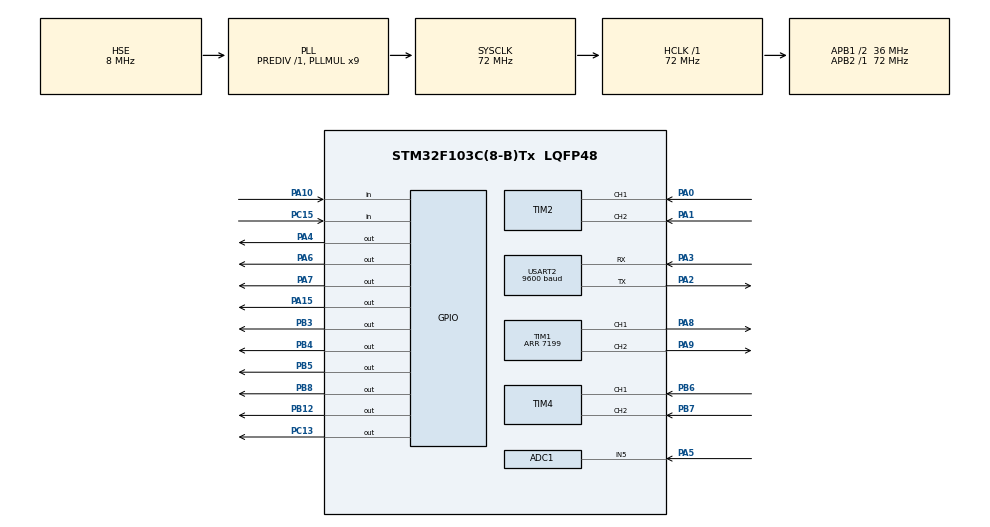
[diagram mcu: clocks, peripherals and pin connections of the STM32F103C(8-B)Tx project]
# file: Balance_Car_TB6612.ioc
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ADC1.Channel-2\#ChannelRegularConversion=ADC_CHANNEL_5
ADC1.NbrOfConversionFlag=1
ADC1.Rank-2\#ChannelRegularConversion=1
ADC1.SamplingTime-2\#ChannelRegularConversion=ADC_SAMPLETIME_1CYCLE_5
ADC1.master=1
Mcu.Family=STM32F1
Mcu.Name=STM32F103C(8-B)Tx
Mcu.Package=LQFP48
NVIC.PriorityGroup=NVIC_PRIORITYGROUP_4
NVIC.TIM3_IRQn=true\:0\:0\:false\:false\:true\:true\:true\:true
NVIC.USART2_IRQn=true\:2\:0\:true\:false\:true\:true\:true\:true
PA0-WKUP.Signal=S_TIM2_CH1_ETR
PA1.Signal=S_TIM2_CH2
PA10.GPIO_PuPd=GPIO_PULLUP
PA10.Signal=GPIO_Input
PA13.Mode=Serial_Wire
PA13.Signal=SYS_JTMS-SWDIO
PA14.Mode=Serial_Wire
PA14.Signal=SYS_JTCK-SWCLK
PA15.Signal=GPIO_Output
PA2.Mode=Asynchronous
PA2.Signal=USART2_TX
PA3.Mode=Asynchronous
PA3.Signal=USART2_RX
PA4.GPIO_Speed=GPIO_SPEED_FREQ_LOW
PA4.PinState=GPIO_PIN_SET
PA4.Signal=GPIO_Output
PA5.Signal=ADCx_IN5
PA6.Signal=GPIO_Output
PA7.Signal=GPIO_Output
PA8.Signal=S_TIM1_CH1
PA9.Signal=S_TIM1_CH2
PB12.Signal=GPIO_Output
PB3.Signal=GPIO_Output
PB4.Signal=GPIO_Output
PB5.Signal=GPIO_Output
PB6.Signal=S_TIM4_CH1
PB7.Signal=S_TIM4_CH2
PB8.Signal=GPIO_Output
PC13-TAMPER-RTC.PinState=GPIO_PIN_SET
PC13-TAMPER-RTC.Signal=GPIO_Output
PC15-OSC32_OUT.GPIO_PuPd=GPIO_PULLUP
PC15-OSC32_OUT.Signal=GPIO_Input
PD0-OSC_IN.Mode=HSE-External-Oscillator
PD0-OSC_IN.Signal=RCC_OSC_IN
PD1-OSC_OUT.Mode=HSE-External-Oscillator
PD1-OSC_OUT.Signal=RCC_OSC_OUT
ProjectManager.HeapSize=0x200
ProjectManager.StackSize=0x400
ProjectManager.TargetToolchain=MDK-ARM V5
RCC.ADCPresc=RCC_ADCPCLK2_DIV6
RCC.AHBFreq_Value=72000000
RCC.APB1CLKDivider=RCC_HCLK_DIV2
RCC.APB1Freq_Value=36000000
RCC.APB1TimFreq_Value=72000000
RCC.APB2Freq_Value=72000000
RCC.APB2TimFreq_Value=72000000
RCC.HCLKFreq_Value=72000000
RCC.PLLMUL=RCC_PLL_MUL9
RCC.PLLSourceVirtual=RCC_PLLSOURCE_HSE
RCC.SYSCLKFreq_VALUE=72000000
RCC.SYSCLKSource=RCC_SYSCLKSOURCE_PLLCLK
RCC.USBFreq_Value=72000000
SH.ADCx_IN5.0=ADC1_IN5,IN5
SH.S_TIM1_CH1.0=TIM1_CH1,PWM Generation1 CH1
SH.S_TIM1_CH2.0=TIM1_CH2,PWM Generation2 CH2
SH.S_TIM2_CH1_ETR.0=TIM2_CH1,Encoder_Interface
SH.S_TIM2_CH2.0=TIM2_CH2,Encoder_Interface
SH.S_TIM4_CH1.0=TIM4_CH1,Encoder_Interface
SH.S_TIM4_CH2.0=TIM4_CH2,Encoder_Interface
TIM1.AutoReloadPreload=TIM_AUTORELOAD_PRELOAD_ENABLE
TIM1.Channel-PWM\ Generation1\ CH1=TIM_CHANNEL_1
TIM1.Channel-PWM\ Generation2\ CH2=TIM_CHANNEL_2
TIM1.Period=7199
TIM2.AutoReloadPreload=TIM_AUTORELOAD_PRELOAD_ENABLE
TIM2.EncoderMode=TIM_ENCODERMODE_TI12
TIM3.AutoReloadPreload=TIM_AUTORELOAD_PRELOAD_ENABLE
TIM3.Period=7199
TIM3.Prescaler=99
TIM4.AutoReloadPreload=TIM_AUTORELOAD_PRELOAD_ENABLE
TIM4.EncoderMode=TIM_ENCODERMODE_TI12
USART2.BaudRate=9600
USART2.VirtualMode=VM_ASYNC
VP_IWDG_VS_IWDG.Mode=IWDG_Activate
VP_TIM3_VS_ClockSourceINT.Mode=Internal
board=custom

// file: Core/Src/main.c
/* USER CODE BEGIN Header */
/**
  ******************************************************************************
  * @file           : main.c
  * @brief          : Main program body
  ******************************************************************************
  * @attention
  *
  * Copyright (c) 2022 STMicroelectronics.
  * All rights reserved.
  *
  * This software is licensed under terms that can be found in the LICENSE file
  * in the root directory of this software component.
  * If no LICENSE file comes with this software, it is provided AS-IS.
  *
  ******************************************************************************
  */
/* USER CODE END Header */
#include "main.h"
#include "adc.h"
#include "iwdg.h"
#include "tim.h"
#include "usart.h"
#include "gpio.h"

/* USER CODE BEGIN Includes */
 #include "control.h"
/* USER CODE END Includes */

void SystemClock_Config(void);

int main(void)
{

  /* MCU Configuration--------------------------------------------------------*/

  /* Reset of all peripherals, Initializes the Flash interface and the Systick. */
  HAL_Init();

  /* Configure the system clock */
  SystemClock_Config();

  /* Initialize all configured peripherals */
  MX_IWDG_Init();
	MX_GPIO_Init();
  MX_ADC1_Init();
  MX_TIM1_Init();
  MX_TIM2_Init();
  MX_TIM3_Init();
  MX_TIM4_Init();
  MX_USART2_UART_Init();

  /* USER CODE BEGIN 2 */

	HAL_GPIO_WritePin(GPIOA, GPIO_PIN_4, GPIO_PIN_RESET);
	while(mpu_dmp_init());		//dmp初始化
	TIM_Init();
	printf("OK\n");
	HAL_GPIO_WritePin(GPIOC,GPIO_PIN_13,GPIO_PIN_RESET);
	OLED_Init_show();
	PID_Init();
	HAL_UART_Receive_IT(&huart2,UART_Receive_buffer, 1);//串口2接受中断初始化
  /* USER CODE END 2 */

  /* Infinite loop */
  /* USER CODE BEGIN WHILE */
  while (1)
  {

		HAL_IWDG_Refresh(&hiwdg);

		if(delay_flag)
		{

			OLED_Proc();

			delay_flag=0;
		}
    /* USER CODE END WHILE */

  }
}

void SystemClock_Config(void)
{
  RCC_OscInitTypeDef RCC_OscInitStruct = {0};
  RCC_ClkInitTypeDef RCC_ClkInitStruct = {0};
  RCC_PeriphCLKInitTypeDef PeriphClkInit = {0};

  /** Initializes the RCC Oscillators according to the specified parameters
  * in the RCC_OscInitTypeDef structure.
  */
  RCC_OscInitStruct.OscillatorType = RCC_OSCILLATORTYPE_LSI|RCC_OSCILLATORTYPE_HSE;
  RCC_OscInitStruct.HSEState = RCC_HSE_ON;
  RCC_OscInitStruct.HSEPredivValue = RCC_HSE_PREDIV_DIV1;
  RCC_OscInitStruct.HSIState = RCC_HSI_ON;
  RCC_OscInitStruct.LSIState = RCC_LSI_ON;
  RCC_OscInitStruct.PLL.PLLState = RCC_PLL_ON;
  RCC_OscInitStruct.PLL.PLLSource = RCC_PLLSOURCE_HSE;
  RCC_OscInitStruct.PLL.PLLMUL = RCC_PLL_MUL9;
  if (HAL_RCC_OscConfig(&RCC_OscInitStruct) != HAL_OK)
  {
    Error_Handler();
  }

  /** Initializes the CPU, AHB and APB buses clocks
  */
  RCC_ClkInitStruct.ClockType = RCC_CLOCKTYPE_HCLK|RCC_CLOCKTYPE_SYSCLK
                              |RCC_CLOCKTYPE_PCLK1|RCC_CLOCKTYPE_PCLK2;
  RCC_ClkInitStruct.SYSCLKSource = RCC_SYSCLKSOURCE_PLLCLK;
  RCC_ClkInitStruct.AHBCLKDivider = RCC_SYSCLK_DIV1;
  RCC_ClkInitStruct.APB1CLKDivider = RCC_HCLK_DIV2;
  RCC_ClkInitStruct.APB2CLKDivider = RCC_HCLK_DIV1;

  if (HAL_RCC_ClockConfig(&RCC_ClkInitStruct, FLASH_LATENCY_2) != HAL_OK)
  {
    Error_Handler();
  }
  PeriphClkInit.PeriphClockSelection = RCC_PERIPHCLK_ADC;
  PeriphClkInit.AdcClockSelection = RCC_ADCPCLK2_DIV6;
  if (HAL_RCCEx_PeriphCLKConfig(&PeriphClkInit) != HAL_OK)
  {
    Error_Handler();
  }
}

void Error_Handler(void)
{
  __disable_irq();
  while (1)
  {
  }
}
